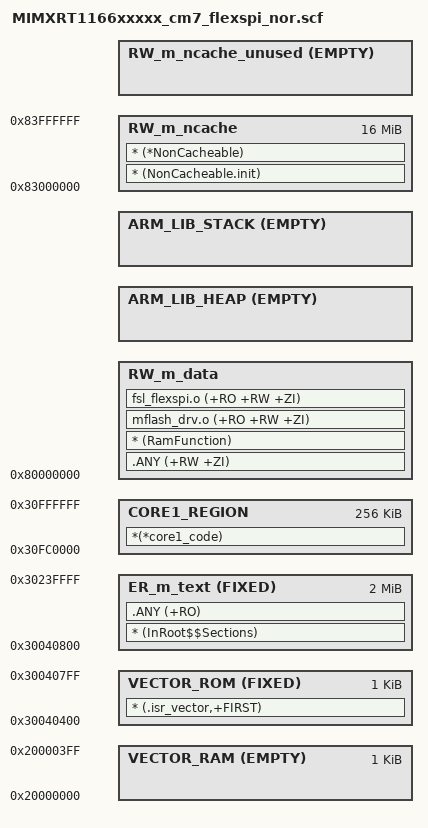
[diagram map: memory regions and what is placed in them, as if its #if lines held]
#!armclang --target=arm-arm-none-eabi -mcpu=cortex-m7 -E -x c
/*
** ###################################################################
**     Processors:          MIMXRT1166CVM5A_cm7
**                          MIMXRT1166DVM6A_cm7
**                          MIMXRT1166XVM5A_cm7
**
**     Compiler:            Keil ARM C/C++ Compiler
**     Reference manual:    IMXRT1160RM, Rev 0, 03/2021
**     Version:             rev. 0.1, 2020-12-29
**     Build:               b210709
**
**     Abstract:
**         Linker file for the Keil ARM C/C++ Compiler
**
**     Copyright 2016 Freescale Semiconductor, Inc.
**     Copyright 2016-2021 NXP
**     All rights reserved.
**
**     SPDX-License-Identifier: BSD-3-Clause
**
**     http:                 www.nxp.com
**     mail:                 support@nxp.com
**
** ###################################################################
*/

#if (defined(__ram_vector_table__))
  #define __ram_vector_table_size__    0x00000400
#else
  #define __ram_vector_table_size__    0x00000000
#endif

#define m_interrupts_start             0x30040400
#define m_interrupts_size              0x00000400

#define m_text_start                   0x30040800
#define m_text_size                    0x001FF800

/* Reserved area for "mflash_files" */
#define  m_mflash_start                0x30D90000
#define  m_mflash_size                 0x00270000

#define m_interrupts_ram_start         0x20000000
#define m_interrupts_ram_size          __ram_vector_table_size__

#define m_data_start                   (m_interrupts_ram_start + m_interrupts_ram_size)
#define m_data_size                    (0x00040000 - m_interrupts_ram_size)

#define m_data2_start                  0x202C2000
#define m_data2_size                   0x00010000

#define m_ncache_start                 0x83000000
#define m_ncache_size                  0x01000000

#define m_data3_start                  0x80000000
#define m_data3_size                   0x03000000

#define m_core1_image_start            0x30FC0000
#define m_core1_image_size             0x00040000

/* Sizes */
#if (defined(__stack_size__))
  #define Stack_Size                   __stack_size__
#else
  #define Stack_Size                   0x0400
#endif

#if (defined(__heap_size__))
  #define Heap_Size                    __heap_size__
#else
  #define Heap_Size                    0x0400
#endif

LR_m_text m_interrupts_start m_text_start+m_text_size-m_interrupts_start {   ; load region size_region
  VECTOR_ROM m_interrupts_start FIXED m_interrupts_size { ; load address = execution address
    * (.isr_vector,+FIRST)
  }
  ER_m_text m_text_start FIXED m_text_size { ; load address = execution address
    * (InRoot$$Sections)
    .ANY (+RO)
  }
#if (defined(__ram_vector_table__))
  VECTOR_RAM m_interrupts_ram_start EMPTY m_interrupts_ram_size {
  }
#else
  VECTOR_RAM m_interrupts_start EMPTY 0 {
  }
#endif
  RW_m_data m_data3_start m_data3_size-Heap_Size { ; RW data
    .ANY (+RW +ZI)
    * (RamFunction)
    /* Necessary to run flash routines from SRAM */
    mflash_drv.o (+RO +RW +ZI)
    fsl_flexspi.o (+RO +RW +ZI)
  }
  ARM_LIB_HEAP +0 EMPTY Heap_Size {    ; Heap region growing up
  }
  ARM_LIB_STACK m_data_start+m_data_size EMPTY -Stack_Size { ; Stack region growing down
  }
  RW_m_ncache m_ncache_start m_ncache_size {
    * (NonCacheable.init)
    * (*NonCacheable)
  }
  RW_m_ncache_unused +0 EMPTY m_ncache_size-ImageLength(RW_m_ncache) { ; Empty region added for MPU configuration
  }
}

LR_CORE1_IMAGE m_core1_image_start {
  CORE1_REGION m_core1_image_start m_core1_image_size {
    *(*core1_code)
  }
}
